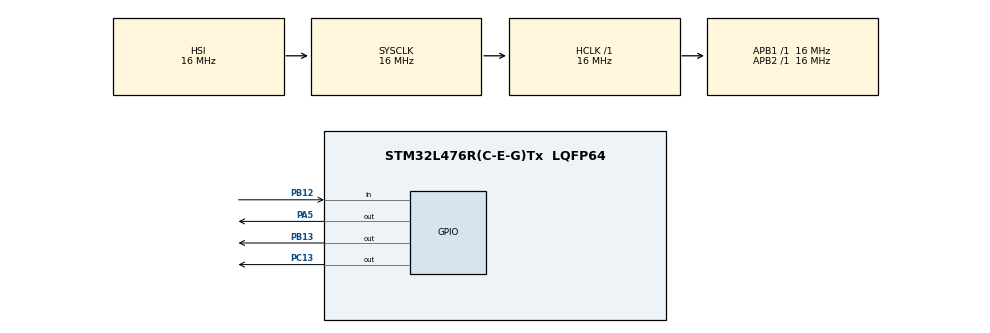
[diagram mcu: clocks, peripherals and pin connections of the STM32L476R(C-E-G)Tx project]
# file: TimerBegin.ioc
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Mcu.Family=STM32L4
Mcu.Name=STM32L476R(C-E-G)Tx
Mcu.Package=LQFP64
NVIC.PriorityGroup=NVIC_PRIORITYGROUP_4
NVIC.TIM1_UP_TIM16_IRQn=true\:0\:0\:false\:false\:true\:true
PA5.Signal=GPIO_Output
PB12.Signal=GPIO_Input
PB13.Signal=GPIO_Output
PC13.Signal=GPIO_Output
ProjectManager.HeapSize=0x200
ProjectManager.StackSize=0x400
ProjectManager.TargetToolchain=TrueSTUDIO
RCC.AHBFreq_Value=16000000
RCC.APB1Freq_Value=16000000
RCC.APB1TimFreq_Value=16000000
RCC.APB2Freq_Value=16000000
RCC.APB2TimFreq_Value=16000000
RCC.CortexFreq_Value=16000000
RCC.HCLKFreq_Value=16000000
RCC.HSE_VALUE=8000000
RCC.HSI_VALUE=16000000
RCC.LSE_VALUE=32768
RCC.MSI_VALUE=4000000
RCC.SYSCLKFreq_VALUE=16000000
RCC.SYSCLKSource=RCC_SYSCLKSOURCE_HSI
RCC.VCOOutputFreq_Value=32000000
TIM1.Period=500
TIM1.Prescaler=16000
VP_TIM1_VS_ClockSourceINT.Mode=Internal
board=TimerBegin

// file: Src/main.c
/**
  ******************************************************************************
  * File Name          : main.c
  * Description        : Main program body
  ******************************************************************************
  ** This notice applies to any and all portions of this file
  * that are not between comment pairs USER CODE BEGIN and
  * USER CODE END. Other portions of this file, whether
  * inserted by the user or by software development tools
  * are owned by their respective copyright owners.
  *
  * COPYRIGHT(c) 2019 STMicroelectronics
  *
  * Redistribution and use in source and binary forms, with or without modification,
  * are permitted provided that the following conditions are met:
  *   1. Redistributions of source code must retain the above copyright notice,
  *      this list of conditions and the following disclaimer.
  *   2. Redistributions in binary form must reproduce the above copyright notice,
  *      this list of conditions and the following disclaimer in the documentation
  *      and/or other materials provided with the distribution.
  *   3. Neither the name of STMicroelectronics nor the names of its contributors
  *      may be used to endorse or promote products derived from this software
  *      without specific prior written permission.
  *
  * THIS SOFTWARE IS PROVIDED BY THE COPYRIGHT HOLDERS AND CONTRIBUTORS "AS IS"
  * AND ANY EXPRESS OR IMPLIED WARRANTIES, INCLUDING, BUT NOT LIMITED TO, THE
  * IMPLIED WARRANTIES OF MERCHANTABILITY AND FITNESS FOR A PARTICULAR PURPOSE ARE
  * DISCLAIMED. IN NO EVENT SHALL THE COPYRIGHT HOLDER OR CONTRIBUTORS BE LIABLE
  * FOR ANY DIRECT, INDIRECT, INCIDENTAL, SPECIAL, EXEMPLARY, OR CONSEQUENTIAL
  * DAMAGES (INCLUDING, BUT NOT LIMITED TO, PROCUREMENT OF SUBSTITUTE GOODS OR
  * SERVICES; LOSS OF USE, DATA, OR PROFITS; OR BUSINESS INTERRUPTION) HOWEVER
  * CAUSED AND ON ANY THEORY OF LIABILITY, WHETHER IN CONTRACT, STRICT LIABILITY,
  * OR TORT (INCLUDING NEGLIGENCE OR OTHERWISE) ARISING IN ANY WAY OUT OF THE USE
  * OF THIS SOFTWARE, EVEN IF ADVISED OF THE POSSIBILITY OF SUCH DAMAGE.
  *
  ******************************************************************************
  */

#include "main.h"
#include "stm32l4xx_hal.h"

TIM_HandleTypeDef htim1;

/* USER CODE BEGIN PV */
/* Private variables ---------------------------------------------------------*/

/* USER CODE END PV */

void SystemClock_Config(void);
static void MX_GPIO_Init(void);
static void MX_TIM1_Init(void);

/* USER CODE BEGIN PFP */
/* Private function prototypes -----------------------------------------------*/

/* USER CODE END PFP */

#define AutoReload_T3_5 42000//tim6
int main(void)
{

  /* MCU Configuration----------------------------------------------------------*/

  /* Reset of all peripherals, Initializes the Flash interface and the Systick. */
  HAL_Init();

  /* Configure the system clock */
  SystemClock_Config();

  /* Initialize all configured peripherals */
  MX_GPIO_Init();
  MX_TIM1_Init();

  HAL_TIM_Base_Start_IT(&htim1); // ������ �������

  /* USER CODE BEGIN 2 */
//  ProtectAttempt1();
//  ProtectAttempt2();
  ProtectAttempt3();
  /* USER CODE END 2 */

  /* Infinite loop */
  while (1)
  {

  /* USER CODE BEGIN 3 */

//		__HAL_TIM_DISABLE(&htim1); //HAL_TIM_DisableCounter(TIM6);
//		__HAL_TIM_SET_COUNTER(&htim1, 0); //HAL_TIM_SetCounter(TIM6, 0);
//		__HAL_TIM_CLEAR_FLAG(&htim1, TIM_FLAG_UPDATE); // HAL_TIM_ClearFlag_UPDATE(TIM6);
////		__HAL_TIM_SET_AUTORELOAD(&htim1, AutoReload_T3_5); //HAL_TIM_SetAutoReload(TIM6, AutoReload_T3_5);
//		__HAL_TIM_ENABLE_IT(&htim1, TIM_IT_UPDATE); //HAL_TIM_EnableIT_UPDATE(TIM6);
//		__HAL_TIM_ENABLE(&htim1); //HAL_TIM_EnableCounter(TIM6);
//		HAL_GPIO_TogglePin(GPIOA, GPIO_PIN_5);
		HAL_Delay(3000);
		HAL_GPIO_WritePin(GPIOA, GPIO_PIN_5, GPIO_PIN_SET);
		HAL_Delay(70);
		HAL_GPIO_WritePin(GPIOA, GPIO_PIN_5, GPIO_PIN_RESET);

  }
  /* USER CODE END 3 */

}

void ProtectAttempt1(void)
{
    FLASH_OBProgramInitTypeDef optionsbytes = {0};
    HAL_StatusTypeDef status;

    optionsbytes.OptionType = OPTIONBYTE_RDP;
    optionsbytes.RDPLevel = OB_RDP_LEVEL_2;
    status = HAL_FLASHEx_OBProgram(&optionsbytes);
    if (status != HAL_OK) {
        asm("nop");
    }
}

void ProtectAttempt2(void)
{
	  FLASH_OBProgramInitTypeDef Optbyte;

	  __disable_irq();
	  HAL_FLASHEx_OBGetConfig(&Optbyte);   	// read out RDPLvL
	  if(Optbyte.RDPLevel == OB_RDP_LEVEL_0){   //
	    Optbyte.OptionType=OPTIONBYTE_RDP; 	// select RDP optionbyte
	    Optbyte.RDPLevel=OB_RDP_LEVEL_1;   	// select RDP level 1
	    HAL_FLASH_Unlock();                	// unlock Flash
	    HAL_FLASH_OB_Unlock();             	// unlock Optionbytes
	    HAL_FLASHEx_OBProgram(&Optbyte);   	// set RDP=1
	    HAL_FLASH_OB_Launch();             	// write OB to Flash and reset
	    HAL_FLASH_OB_Lock();                // Lock Optionbytes
	    HAL_FLASH_Lock();                   // lock Flash
	  }
	  __enable_irq();
}

void ProtectAttempt3(void)
{
	FLASH_OBProgramInitTypeDef OBInit;
	 __disable_irq();
	HAL_FLASHEx_OBGetConfig( (FLASH_OBProgramInitTypeDef *)&OBInit );
	if (OBInit.RDPLevel != OB_RDP_LEVEL_1)
	{
		OBInit.OptionType = OPTIONBYTE_RDP;
		OBInit.RDPLevel = OB_RDP_LEVEL_1;
		HAL_FLASH_Unlock();
//		HAL_FLASH_OB_Unlock();
		HAL_FLASHEx_OBProgram( (FLASH_OBProgramInitTypeDef *)&OBInit );
		HAL_FLASH_OB_Launch();
//		HAL_FLASH_OB_Lock();
		HAL_FLASH_Lock();
	}
	__enable_irq();
}

/** System Clock Configuration
*/
void SystemClock_Config(void)
{

  RCC_OscInitTypeDef RCC_OscInitStruct;
  RCC_ClkInitTypeDef RCC_ClkInitStruct;

    /**Initializes the CPU, AHB and APB busses clocks
    */
  RCC_OscInitStruct.OscillatorType = RCC_OSCILLATORTYPE_HSI;
  RCC_OscInitStruct.HSIState = RCC_HSI_ON;
  RCC_OscInitStruct.HSICalibrationValue = 16;
  RCC_OscInitStruct.PLL.PLLState = RCC_PLL_NONE;
  if (HAL_RCC_OscConfig(&RCC_OscInitStruct) != HAL_OK)
  {
    _Error_Handler(__FILE__, __LINE__);
  }

    /**Initializes the CPU, AHB and APB busses clocks
    */
  RCC_ClkInitStruct.ClockType = RCC_CLOCKTYPE_HCLK|RCC_CLOCKTYPE_SYSCLK
                              |RCC_CLOCKTYPE_PCLK1|RCC_CLOCKTYPE_PCLK2;
  RCC_ClkInitStruct.SYSCLKSource = RCC_SYSCLKSOURCE_HSI;
  RCC_ClkInitStruct.AHBCLKDivider = RCC_SYSCLK_DIV1;
  RCC_ClkInitStruct.APB1CLKDivider = RCC_HCLK_DIV1;
  RCC_ClkInitStruct.APB2CLKDivider = RCC_HCLK_DIV1;

  if (HAL_RCC_ClockConfig(&RCC_ClkInitStruct, FLASH_LATENCY_0) != HAL_OK)
  {
    _Error_Handler(__FILE__, __LINE__);
  }

    /**Configure the main internal regulator output voltage
    */
  if (HAL_PWREx_ControlVoltageScaling(PWR_REGULATOR_VOLTAGE_SCALE1) != HAL_OK)
  {
    _Error_Handler(__FILE__, __LINE__);
  }

    /**Configure the Systick interrupt time
    */
  HAL_SYSTICK_Config(HAL_RCC_GetHCLKFreq()/1000);

    /**Configure the Systick
    */
  HAL_SYSTICK_CLKSourceConfig(SYSTICK_CLKSOURCE_HCLK);

  /* SysTick_IRQn interrupt configuration */
  HAL_NVIC_SetPriority(SysTick_IRQn, 0, 0);
}

/* TIM1 init function */
static void MX_TIM1_Init(void)
{

//  TIM_ClockConfigTypeDef sClockSourceConfig;
  TIM_MasterConfigTypeDef sMasterConfig;

  htim1.Instance = TIM1;
  htim1.Init.Prescaler = 1;
  htim1.Init.CounterMode = TIM_COUNTERMODE_UP;
  htim1.Init.Period = 10000;
//  htim1.Init.ClockDivision = TIM_CLOCKDIVISION_DIV1;
//  htim1.Init.RepetitionCounter = 0;
  htim1.Init.AutoReloadPreload = TIM_AUTORELOAD_PRELOAD_DISABLE;
  if (HAL_TIM_Base_Init(&htim1) != HAL_OK)
  {
    _Error_Handler(__FILE__, __LINE__);
  }

//  sClockSourceConfig.ClockSource = TIM_CLOCKSOURCE_INTERNAL;
//  if (HAL_TIM_ConfigClockSource(&htim1, &sClockSourceConfig) != HAL_OK)
//  {
//    _Error_Handler(__FILE__, __LINE__);
//  }

	if (HAL_TIM_OnePulse_Init(&htim1, TIM_OPMODE_SINGLE) != HAL_OK)
	{
		_Error_Handler(__FILE__, __LINE__);
	}

  sMasterConfig.MasterOutputTrigger = TIM_TRGO_RESET;
//  sMasterConfig.MasterOutputTrigger2 = TIM_TRGO2_RESET;
  sMasterConfig.MasterSlaveMode = TIM_MASTERSLAVEMODE_DISABLE;
  if (HAL_TIMEx_MasterConfigSynchronization(&htim1, &sMasterConfig) != HAL_OK)
  {
    _Error_Handler(__FILE__, __LINE__);
  }

}

/** Configure pins as
        * Analog
        * Input
        * Output
        * EVENT_OUT
        * EXTI
*/
static void MX_GPIO_Init(void)
{

  GPIO_InitTypeDef GPIO_InitStruct;

  /* GPIO Ports Clock Enable */
  __HAL_RCC_GPIOC_CLK_ENABLE();
  __HAL_RCC_GPIOA_CLK_ENABLE();
  __HAL_RCC_GPIOB_CLK_ENABLE();

  /*Configure GPIO pin Output Level */
  HAL_GPIO_WritePin(GPIOC, GPIO_PIN_13, GPIO_PIN_RESET);

  /*Configure GPIO pin Output Level */
  HAL_GPIO_WritePin(GPIOA, GPIO_PIN_5, GPIO_PIN_RESET);

  /*Configure GPIO pin Output Level */
  HAL_GPIO_WritePin(GPIOB, GPIO_PIN_13, GPIO_PIN_RESET);

  /*Configure GPIO pin : PC13 */
  GPIO_InitStruct.Pin = GPIO_PIN_13;
  GPIO_InitStruct.Mode = GPIO_MODE_OUTPUT_PP;
  GPIO_InitStruct.Pull = GPIO_NOPULL;
  GPIO_InitStruct.Speed = GPIO_SPEED_FREQ_LOW;
  HAL_GPIO_Init(GPIOC, &GPIO_InitStruct);

  /*Configure GPIO pin : PA5 */
  GPIO_InitStruct.Pin = GPIO_PIN_5;
  GPIO_InitStruct.Mode = GPIO_MODE_OUTPUT_PP;
  GPIO_InitStruct.Pull = GPIO_NOPULL;
  GPIO_InitStruct.Speed = GPIO_SPEED_FREQ_LOW;
  HAL_GPIO_Init(GPIOA, &GPIO_InitStruct);

  /*Configure GPIO pin : PB12 */
  GPIO_InitStruct.Pin = GPIO_PIN_12;
  GPIO_InitStruct.Mode = GPIO_MODE_INPUT;
  GPIO_InitStruct.Pull = GPIO_NOPULL;
  HAL_GPIO_Init(GPIOB, &GPIO_InitStruct);

  /*Configure GPIO pin : PB13 */
  GPIO_InitStruct.Pin = GPIO_PIN_13;
  GPIO_InitStruct.Mode = GPIO_MODE_OUTPUT_PP;
  GPIO_InitStruct.Pull = GPIO_NOPULL;
  GPIO_InitStruct.Speed = GPIO_SPEED_FREQ_LOW;
  HAL_GPIO_Init(GPIOB, &GPIO_InitStruct);

}

void _Error_Handler(char * file, int line)
{
  while(1)
  {
  }
}

/************************ (C) COPYRIGHT STMicroelectronics *****END OF FILE****/
